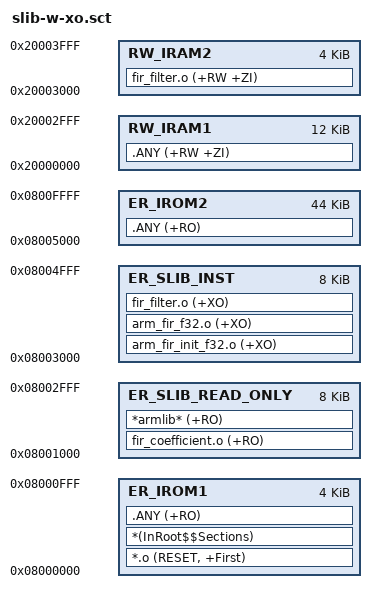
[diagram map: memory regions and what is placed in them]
; *************************************************************
; *** Scatter-Loading Description File generated by uVision ***
; *************************************************************

LR_IROM1 0x08000000 0x001000  {    ; load region size_region
  ER_IROM1 0x08000000 0x001000  {  ; load address = execution address
   *.o (RESET, +First)
   *(InRoot$$Sections)
   .ANY (+RO)
  }
  
  RW_IRAM1 0x20000000 0x00003000  {  ; user RW data
   .ANY (+RW +ZI)
  }
  
  RW_IRAM2 0x20003000 0x00001000  {  ; RAM used for slib code
   fir_filter.o (+RW +ZI) 
  }  
}

; user can also use this section to place slib read-only
LR_SLIB_READ_ONLY 0x08001000 0x00002000  {    ; sLib read-only
  ER_SLIB_READ_ONLY 0x08001000 0x00002000  {  
   fir_coefficient.o (+RO)   
   *armlib* (+RO)  
  }
}

LR_SLIB_INST 0x08003000 0x00002000  {    ; slib inst
  ER_SLIB_INST 0x08003000 0x00002000  {  ; load address = execution address
	arm_fir_init_f32.o (+XO)
	arm_fir_f32.o (+XO)
	fir_filter.o (+XO)
  }
}

LR_IROM2 0x08005000 0x0000B000  {    ; user code area
  ER_IROM2 0x08005000 0x0000B000  {  ; load address = execution address
   .ANY (+RO)
  }
}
